# R7FA2A1AB register map
Vendor: Renesas; Series: RA2; File version: 1.1
CPU: CM23 r1p0, little endian, MPU, no FPU, VTOR, 2 interrupt priority bits
Registers are 8-bit, read-write, reset 0x0 unless marked. A register's access mark holds for its fields unless they carry their own. Offsets are from the block's base; [hi:lo] are bit positions; {n}, {i} and the like mark numbered series.

## OPAMP — OperationalAmplifier
Base 0x40086800
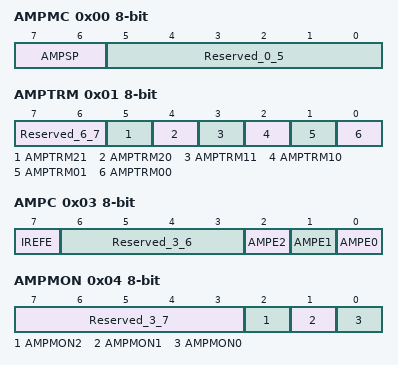
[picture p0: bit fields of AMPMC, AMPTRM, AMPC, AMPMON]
0x00 AMPMC — Operational amplifier mode control register
  [7:6] AMPSP — OPAMP Operation mode selection
  [5:0] Reserved_0_5 — These bits are read as 000000. The write value should be 000000.
0x01 AMPTRM — Operational amplifier trigger mode control register
  [7:6] Reserved_6_7 — These bits are read as 00. The write value should be 00.
  [5] AMPTRM21 — OPAMP function activation/stop trigger control
  [4] AMPTRM20 — OPAMP function activation/stop trigger control
  [3] AMPTRM11 — OPAMP function activation/stop trigger control
  [2] AMPTRM10 — OPAMP function activation/stop trigger control
  [1] AMPTRM01 — OPAMP function activation/stop trigger control
  [0] AMPTRM00 — OPAMP function activation/stop trigger control
0x02 AMPTRS — Operational Amplifier Activation Trigger Select Register
  [1:0] AMPTRS — Activation Trigger SelectionNote: Do not change the value of the AMPTRS register after setting the AMPTRM register.
0x03 AMPC — Operational amplifier control register
  [7] IREFE — Reference Current Circuit Operation Control
  [6:3] Reserved_3_6 — These bits are read as 0000. The write value should be 0000.
  [2] AMPE2 — Operation control of operational amplifier 2
  [1] AMPE1 — Operation control of operational amplifier 1
  [0] AMPE0 — Operation control of operational amplifier 0
0x04 AMPMON ro — Operational amplifier monitor register
  [7:3] Reserved_3_7 — These bits are read as 00000.
  [2] AMPMON2 — OPAMP2 Status
  [1] AMPMON1 — OPAMP1 Status
  [0] AMPMON0 — OPAMP0 Status
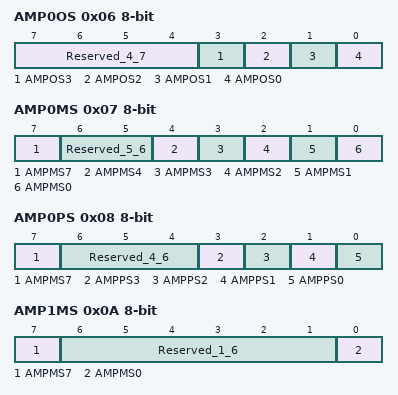
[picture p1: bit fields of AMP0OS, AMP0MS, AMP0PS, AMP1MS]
0x06 AMP0OS — Operational Amplifier 0 Output Select Register
  [7:4] Reserved_4_7 — These bits are read as 0000. The write value should be 0000.
  [3] AMPOS3 — AMP2+ pin select
  [2] AMPOS2 — AMP2- pin select
  [1] AMPOS1 — AMP1+ pin select
  [0] AMPOS0 — AMP1- pin select
0x07 AMP0MS — Operational Amplifier 0 Minus Input Select Register
  [7] AMPMS7 — OPAMP0 output select
  [6:5] Reserved_5_6 — These bits are read as 00. The write value should be 00.
  [4] AMPMS4 — AMP2- pin select
  [3] AMPMS3 — AMP1+ pin select
  [2] AMPMS2 — AMP1- pin select
  [1] AMPMS1 — AMP0+ pin select
  [0] AMPMS0 — AMP0- pin select
0x08 AMP0PS — Operational Amplifier 0 Plus Input Select Register
  [7] AMPMS7 — DAC12 output select
  [6:4] Reserved_4_6 — These bits are read as 000. The write value should be 000.
  [3] AMPPS3 — AMP2+ pin select
  [2] AMPPS2 — AMP1+pin select
  [1] AMPPS1 — AMP1- pin select
  [0] AMPPS0 — AMP0+ pin select
0x0A AMP1MS — Operational Amplifier 1 Minus Input Select Register
  [7] AMPMS7 — OPAMP1 output select
  [6:1] Reserved_1_6 — These bits are read as 000000. The write value should be 000000.
  [0] AMPMS0 — AMP1- pin select
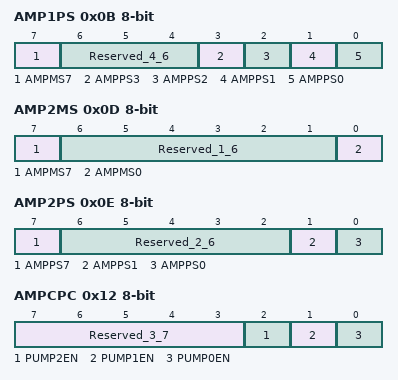
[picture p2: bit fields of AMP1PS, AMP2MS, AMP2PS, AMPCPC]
0x0B AMP1PS — Operational Amplifier 1 Plus Input Select Register
  [7] AMPMS7 — OPAMP2 output select
  [6:4] Reserved_4_6 — These bits are read as 000. The write value should be 000.
  [3] AMPPS3 — AMP2+ pin select
  [2] AMPPS2 — AMP2- pin select
  [1] AMPPS1 — AMP1+ pin select
  [0] AMPPS0 — AMP1- pin select
0x0D AMP2MS — Operational Amplifier 2 Minus Input Select Register
  [7] AMPMS7 — OPAMP2 output select
  [6:1] Reserved_1_6 — These bits are read as 000000. The write value should be 000000.
  [0] AMPMS0 — AMP2- pin select
0x0E AMP2PS — Operational Amplifier 2 Plus Input Select Register
  [7] AMPPS7 — DAC8 channel 1output select
  [6:2] Reserved_2_6 — These bits are read as 00000. The write value should be 00000.
  [1] AMPPS1 — AMP2+ pin select
  [0] AMPPS0 — AMP2- pin select
0x12 AMPCPC — Operational Amplifier Switch Charge Pump Control Register
  [7:3] Reserved_3_7 — These bits are read as 00000. The write value should be 00000.
  [2] PUMP2EN — Charge Pump for AMP2 Enable
  [1] PUMP1EN — Charge Pump for AMP1 Enable
  [0] PUMP0EN — Charge Pump for AMP0 Enable
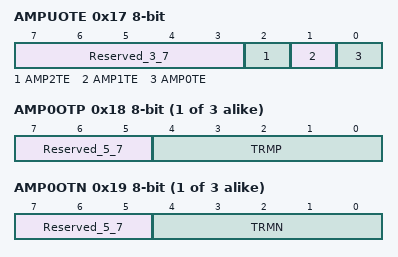
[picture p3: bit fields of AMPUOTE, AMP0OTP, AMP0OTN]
0x17 AMPUOTE — Operational Amplifier User Offset Trimming Enable Register
  [7:3] Reserved_3_7 — These bits are read as 00000. The write value should be 00000.
  [2] AMP2TE — AMP2OT write enable
  [1] AMP1TE — AMP1OT write enable
  [0] AMP0TE — AMP0OT write enable
{0x18+2i} AMP{i}OTP (reset mask 0xE0) (i=0..2) — Operational Amplifier {i} Offset Trimming Pch Register
  [7:5] Reserved_5_7 — These bits are read as 000. The write value should be 000.
  [4:0] TRMP — AMP{i} input offset trimming Pch side
{0x19+2i} AMP{i}OTN (reset mask 0xE0) (i=0..2) — Operational Amplifier {i} Offset Trimming Nch Register
  [7:5] Reserved_5_7 — These bits are read as 000. The write value should be 000.
  [4:0] TRMN — AMP{i} input offset trimming Nch side
